# ES32F36xx register map
File version: 1.0
Registers are 32-bit, read-write, reset 0x0 unless marked. A register's access mark holds for its fields unless they carry their own. Offsets are from the block's base; [hi:lo] are bit positions.

## BS16T0
Base 0x40001000
Same registers: BS16T1 0x40001400
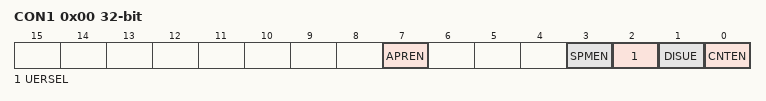
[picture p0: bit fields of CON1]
0x00 CON1
  [7] APREN, [3] SPMEN, [2] UERSEL, [1] DISUE, [0] CNTEN
0x0C IER write
  [0] UIT
0x10 IDR write
  [0] UI
0x14 IVS read
  [0] UEI
0x18 RIF read
  [0] UEVTIF
0x1C IFM read
  [0] UEI
0x20 ICR clear-write1
  [0] UEIC
0x24 SGE write
  [0] SGU
0x34 COUNT
  [15:0] CNTV
0x38 PRES
  [15:0] PSCV
0x3C AR reset 0xFFFF
  [15:0] ARRV
0x58 DMAEN
  [0] UDEN

## USB — Universal Serial Bus
Base 0x40086400
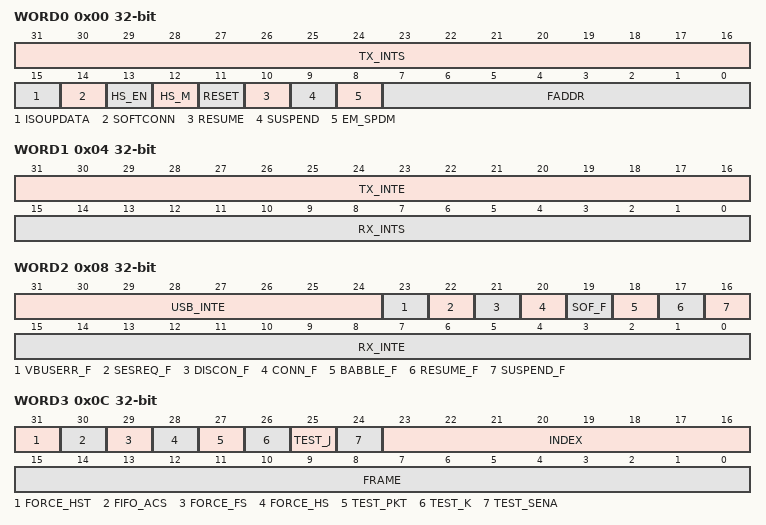
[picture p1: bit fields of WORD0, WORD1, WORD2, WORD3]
0x00 WORD0
  [31:16] TX_INTS, [15] ISOUPDATA, [14] SOFTCONN, [13] HS_EN, [12] HS_M, [11] RESET, [10] RESUME, [9] SUSPEND, [8] EM_SPDM, [7:0] FADDR
0x04 WORD1
  [31:16] TX_INTE, [15:0] RX_INTS
0x08 WORD2
  [31:24] USB_INTE, [23] VBUSERR_F, [22] SESREQ_F, [21] DISCON_F, [20] CONN_F, [19] SOF_F, [18] BABBLE_F, [17] RESUME_F, [16] SUSPEND_F, [15:0] RX_INTE
0x0C WORD3
  [31] FORCE_HST, [30] FIFO_ACS, [29] FORCE_FS, [28] FORCE_HS, [27] TEST_PKT, [26] TEST_K, [25] TEST_J, [24] TEST_SENA, [23:16] INDEX, [15:0] FRAME
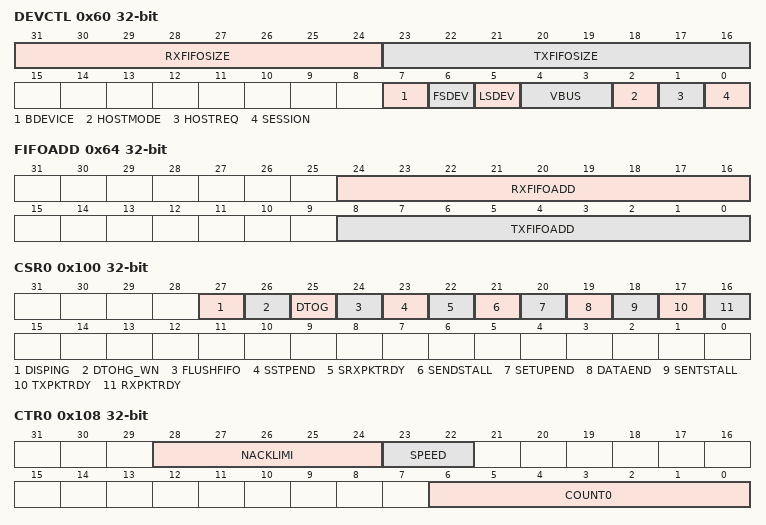
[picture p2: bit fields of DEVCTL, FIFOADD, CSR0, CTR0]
0x60 DEVCTL
  [31:24] RXFIFOSIZE, [23:16] TXFIFOSIZE, [7] BDEVICE, [6] FSDEV, [5] LSDEV, [4:3] VBUS, [2] HOSTMODE, [1] HOSTREQ, [0] SESSION
0x64 FIFOADD
  [24:16] RXFIFOADD, [8:0] TXFIFOADD
0x100 CSR0
  [27] DISPING, [26] DTOHG_WN, [25] DTOG, [24] FLUSHFIFO, [23] SSTPEND, [22] SRXPKTRDY, [21] SENDSTALL, [20] SETUPEND, [19] DATAEND, [18] SENTSTALL, [17] TXPKTRDY, [16] RXPKTRDY
0x108 CTR0
  [28:24] NACKLIMI, [23:22] SPEED, [6:0] COUNT0
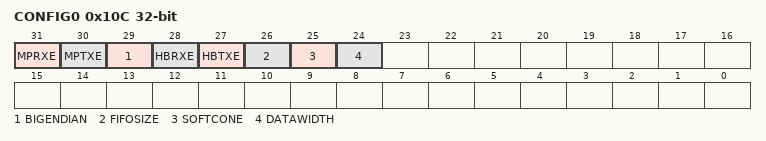
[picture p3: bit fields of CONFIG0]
0x10C CONFIG0
  [31] MPRXE, [30] MPTXE, [29] BIGENDIAN, [28] HBRXE, [27] HBTXE, [26] FIFOSIZE, [25] SOFTCONE, [24] DATAWIDTH

## SPI0
Base 0x40006000
Same registers: SPI1 0x40006400, SPI2 0x40006800
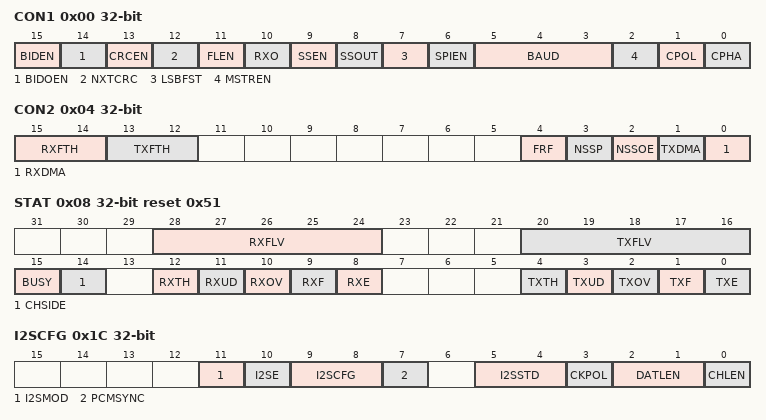
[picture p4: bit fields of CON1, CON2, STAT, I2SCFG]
0x00 CON1
  [15] BIDEN, [14] BIDOEN, [13] CRCEN, [12] NXTCRC, [11] FLEN, [10] RXO, [9] SSEN, [8] SSOUT, [7] LSBFST, [6] SPIEN, [5:3] BAUD, [2] MSTREN, [1] CPOL, [0] CPHA
0x04 CON2
  [15:14] RXFTH, [13:12] TXFTH, [4] FRF, [3] NSSP, [2] NSSOE, [1] TXDMA, [0] RXDMA
0x08 STAT read reset 0x51
  [28:24] RXFLV, [20:16] TXFLV, [15] BUSY, [14] CHSIDE, [12] RXTH, [11] RXUD, [10] RXOV, [9] RXF, [8] RXE, [4] TXTH, [3] TXUD, [2] TXOV, [1] TXF, [0] TXE
0x0C DATA
  [15:0] DATA
0x10 CRCPOLY reset 0x7
  [15:0] CRCPOLY
0x14 RXCRC read
  [15:0] RXCRC
0x18 TXCRC read
  [15:0] TXCRC
0x1C I2SCFG
  [11] I2SMOD, [10] I2SE, [9:8] I2SCFG, [7] PCMSYNC, [5:4] I2SSTD, [3] CKPOL, [2:1] DATLEN, [0] CHLEN
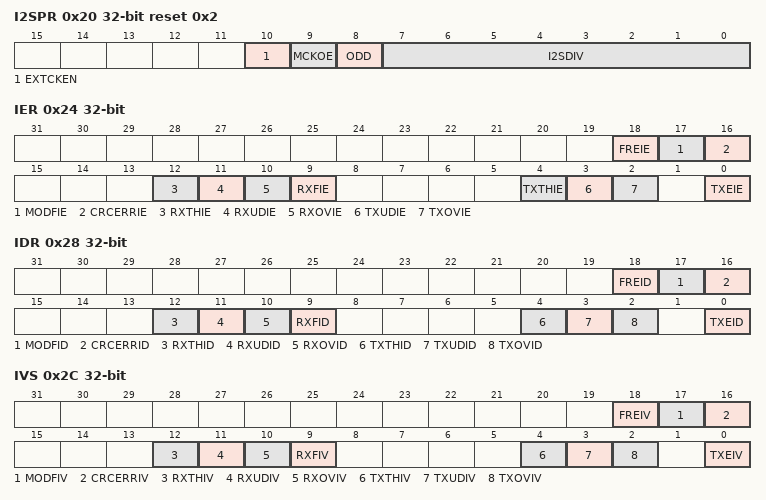
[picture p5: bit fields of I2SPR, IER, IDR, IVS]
0x20 I2SPR reset 0x2
  [10] EXTCKEN, [9] MCKOE, [8] ODD, [7:0] I2SDIV
0x24 IER write1
  [18] FREIE, [17] MODFIE, [16] CRCERRIE, [12] RXTHIE, [11] RXUDIE, [10] RXOVIE, [9] RXFIE, [4] TXTHIE, [3] TXUDIE, [2] TXOVIE, [0] TXEIE
0x28 IDR write1
  [18] FREID, [17] MODFID, [16] CRCERRID, [12] RXTHID, [11] RXUDID, [10] RXOVID, [9] RXFID, [4] TXTHID, [3] TXUDID, [2] TXOVID, [0] TXEID
0x2C IVS read
  [18] FREIV, [17] MODFIV, [16] CRCERRIV, [12] RXTHIV, [11] RXUDIV, [10] RXOVIV, [9] RXFIV, [4] TXTHIV, [3] TXUDIV, [2] TXOVIV, [0] TXEIV
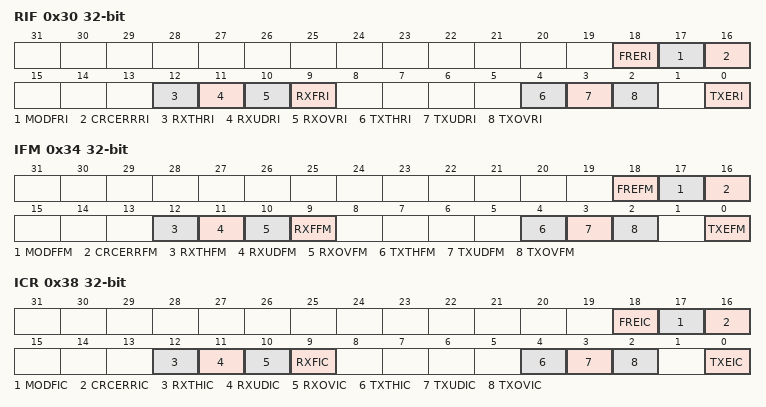
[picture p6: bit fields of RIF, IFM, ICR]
0x30 RIF read
  [18] FRERI, [17] MODFRI, [16] CRCERRRI, [12] RXTHRI, [11] RXUDRI, [10] RXOVRI, [9] RXFRI, [4] TXTHRI, [3] TXUDRI, [2] TXOVRI, [0] TXERI
0x34 IFM read
  [18] FREFM, [17] MODFFM, [16] CRCERRFM, [12] RXTHFM, [11] RXUDFM, [10] RXOVFM, [9] RXFFM, [4] TXTHFM, [3] TXUDFM, [2] TXOVFM, [0] TXEFM
0x38 ICR clear-write1
  [18] FREIC, [17] MODFIC, [16] CRCERRIC, [12] RXTHIC, [11] RXUDIC, [10] RXOVIC, [9] RXFIC, [4] TXTHIC, [3] TXUDIC, [2] TXOVIC, [0] TXEIC

## I2C0
Base 0x40008000
Same registers: I2C1 0x40008400
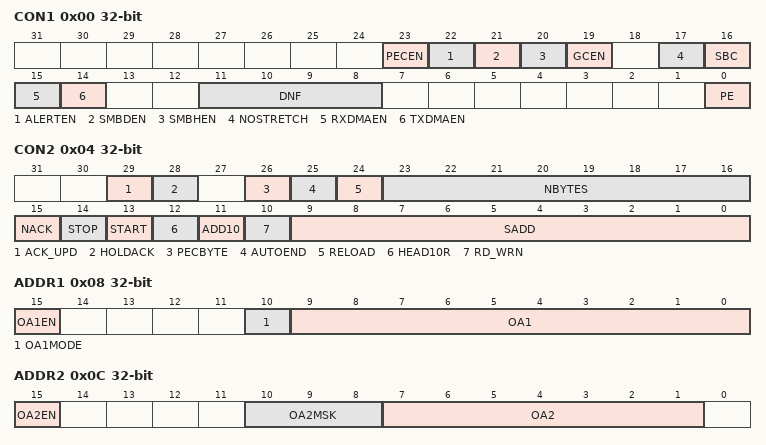
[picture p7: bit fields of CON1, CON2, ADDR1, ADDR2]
0x00 CON1
  [23] PECEN, [22] ALERTEN, [21] SMBDEN, [20] SMBHEN, [19] GCEN, [17] NOSTRETCH, [16] SBC, [15] RXDMAEN, [14] TXDMAEN, [11:8] DNF, [0] PE
0x04 CON2
  [29] ACK_UPD, [28] HOLDACK, [26] PECBYTE, [25] AUTOEND, [24] RELOAD, [23:16] NBYTES, [15] NACK, [14] STOP, [13] START, [12] HEAD10R, [11] ADD10, [10] RD_WRN, [9:0] SADD
0x08 ADDR1
  [15] OA1EN, [10] OA1MODE, [9:0] OA1
0x0C ADDR2
  [15] OA2EN, [10:8] OA2MSK, [7:1] OA2
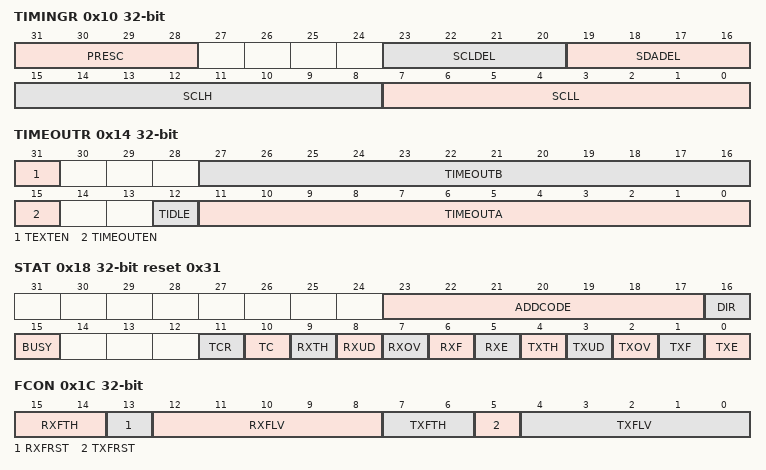
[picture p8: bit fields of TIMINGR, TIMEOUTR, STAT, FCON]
0x10 TIMINGR
  [31:28] PRESC, [23:20] SCLDEL, [19:16] SDADEL, [15:8] SCLH, [7:0] SCLL
0x14 TIMEOUTR
  [31] TEXTEN, [27:16] TIMEOUTB, [15] TIMEOUTEN, [12] TIDLE, [11:0] TIMEOUTA
0x18 STAT read reset 0x31
  [23:17] ADDCODE, [16] DIR, [15] BUSY, [11] TCR, [10] TC, [9] RXTH, [8] RXUD, [7] RXOV, [6] RXF, [5] RXE, [4] TXTH, [3] TXUD, [2] TXOV, [1] TXF, [0] TXE
0x1C FCON read
  [15:14] RXFTH rw, [13] RXFRST write1, [12:8] RXFLV, [7:6] TXFTH rw, [5] TXFRST write1, [4:0] TXFLV
0x20 PECR read
  [7:0] PEC
0x24 RXDATA read
  [7:0] RXDATA
0x28 TXDATA write
  [7:0] TXDATA
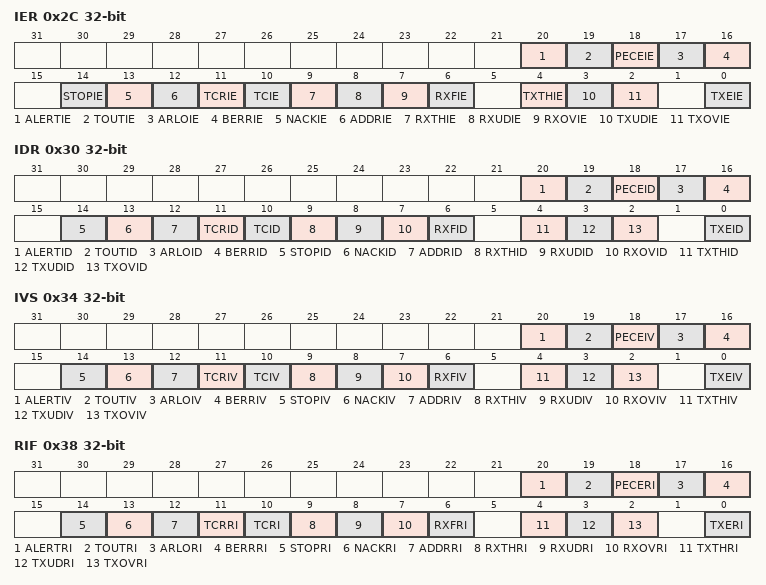
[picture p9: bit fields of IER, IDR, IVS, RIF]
0x2C IER write1
  [20] ALERTIE, [19] TOUTIE, [18] PECEIE, [17] ARLOIE, [16] BERRIE, [14] STOPIE, [13] NACKIE, [12] ADDRIE, [11] TCRIE, [10] TCIE, [9] RXTHIE, [8] RXUDIE, [7] RXOVIE, [6] RXFIE, [4] TXTHIE, [3] TXUDIE, [2] TXOVIE, [0] TXEIE
0x30 IDR write1
  [20] ALERTID, [19] TOUTID, [18] PECEID, [17] ARLOID, [16] BERRID, [14] STOPID, [13] NACKID, [12] ADDRID, [11] TCRID, [10] TCID, [9] RXTHID, [8] RXUDID, [7] RXOVID, [6] RXFID, [4] TXTHID, [3] TXUDID, [2] TXOVID, [0] TXEID
0x34 IVS read
  [20] ALERTIV, [19] TOUTIV, [18] PECEIV, [17] ARLOIV, [16] BERRIV, [14] STOPIV, [13] NACKIV, [12] ADDRIV, [11] TCRIV, [10] TCIV, [9] RXTHIV, [8] RXUDIV, [7] RXOVIV, [6] RXFIV, [4] TXTHIV, [3] TXUDIV, [2] TXOVIV, [0] TXEIV
0x38 RIF read
  [20] ALERTRI, [19] TOUTRI, [18] PECERI, [17] ARLORI, [16] BERRRI, [14] STOPRI, [13] NACKRI, [12] ADDRRI, [11] TCRRI, [10] TCRI, [9] RXTHRI, [8] RXUDRI, [7] RXOVRI, [6] RXFRI, [4] TXTHRI, [3] TXUDRI, [2] TXOVRI, [0] TXERI
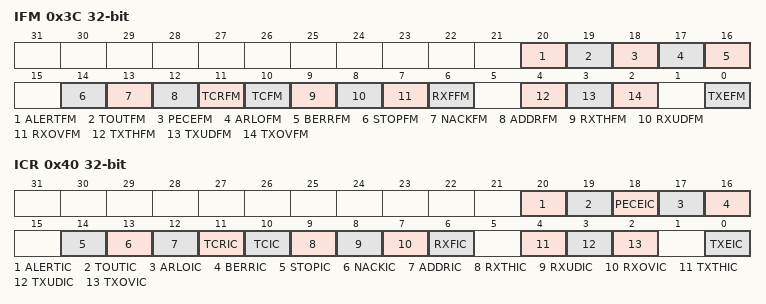
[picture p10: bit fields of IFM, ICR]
0x3C IFM read
  [20] ALERTFM, [19] TOUTFM, [18] PECEFM, [17] ARLOFM, [16] BERRFM, [14] STOPFM, [13] NACKFM, [12] ADDRFM, [11] TCRFM, [10] TCFM, [9] RXTHFM, [8] RXUDFM, [7] RXOVFM, [6] RXFFM, [4] TXTHFM, [3] TXUDFM, [2] TXOVFM, [0] TXEFM
0x40 ICR clear-write1
  [20] ALERTIC, [19] TOUTIC, [18] PECEIC, [17] ARLOIC, [16] BERRIC, [14] STOPIC, [13] NACKIC, [12] ADDRIC, [11] TCRIC, [10] TCIC, [9] RXTHIC, [8] RXUDIC, [7] RXOVIC, [6] RXFIC, [4] TXTHIC, [3] TXUDIC, [2] TXOVIC, [0] TXEIC
